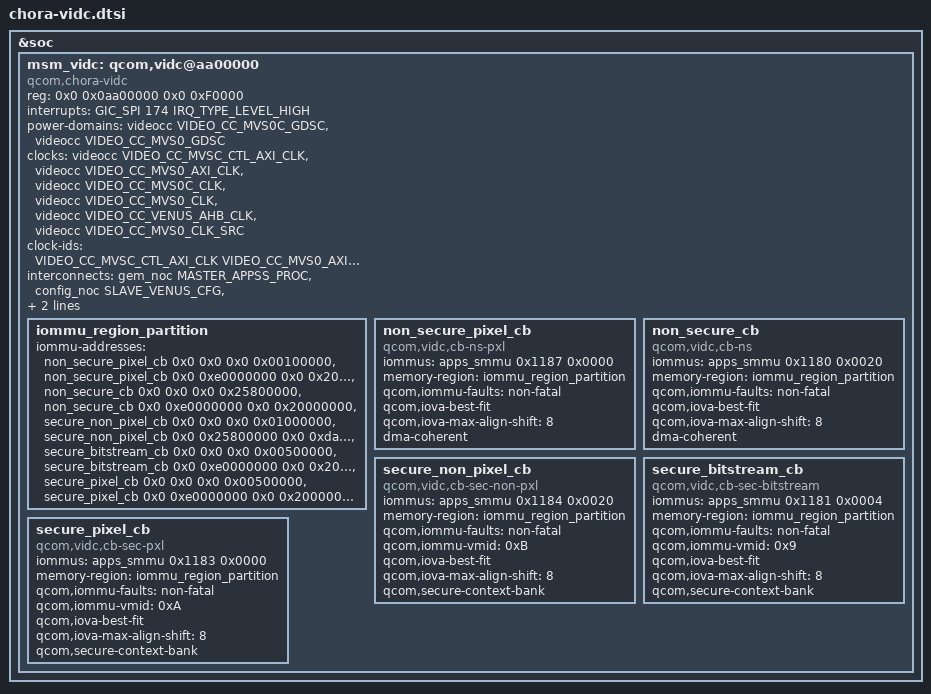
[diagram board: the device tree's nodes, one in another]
// SPDX-License-Identifier: BSD-3-Clause
/*
 * Copyright (c) Qualcomm Technologies, Inc. and/or its subsidiaries.
 */

&soc {
	msm_vidc: qcom,vidc@aa00000 {
		compatible = "qcom,chora-vidc";
		status = "okay";

		/* IOMMU Config */
		#address-cells = <2>;
		#size-cells = <2>;

		reg = <0x0 0x0aa00000 0x0  0xF0000>;
		interrupts = <GIC_SPI 174 IRQ_TYPE_LEVEL_HIGH>;

		/* Power Domains */
		power-domains = <&videocc VIDEO_CC_MVS0C_GDSC>,
				<&videocc VIDEO_CC_MVS0_GDSC>;
		power-domain-names = "iris-ctl", "vcodec";

		/* Clocks */
		clocks =
			<&videocc VIDEO_CC_MVSC_CTL_AXI_CLK>,
			<&videocc VIDEO_CC_MVS0_AXI_CLK>,
			<&videocc VIDEO_CC_MVS0C_CLK>,
			<&videocc VIDEO_CC_MVS0_CLK>,
			<&videocc VIDEO_CC_VENUS_AHB_CLK>,
			<&videocc VIDEO_CC_MVS0_CLK_SRC>;
		clock-names =
			"video_ctl_axi_clk",
			"video_mvs0_axi_clk",
			"core_clk",
			"vcodec_clk",
			"iface_clk",
			"video_cc_iris_clk_src";
		clock-ids =
			<VIDEO_CC_MVSC_CTL_AXI_CLK
			VIDEO_CC_MVS0_AXI_CLK
			VIDEO_CC_MVS0C_CLK
			VIDEO_CC_MVS0_CLK
			VIDEO_CC_VENUS_AHB_CLK
			VIDEO_CC_MVS0_CLK_SRC>;

		/* Bus Interconnects uncommenting this causing issue */
		interconnects =
			<&gem_noc MASTER_APPSS_PROC &config_noc SLAVE_VENUS_CFG>,
			<&mmss_noc MASTER_VIDEO &mc_virt SLAVE_EBI1>;
		interconnect-names =
			"venus-cnoc",
			"venus-ddr";

		memory-region = <&video_mem>;

		/* MMUs */
		iommu_region_partition: iommu_region_partition {
			/* These IOVA regions are unique per context bank */
			iommu-addresses = <&non_secure_pixel_cb 0x0 0x0 0x0 0x00100000>,
				<&non_secure_pixel_cb 0x0 0xe0000000 0x0 0x20000000>,
				<&non_secure_cb 0x0 0x0 0x0 0x25800000>,
				<&non_secure_cb 0x0 0xe0000000 0x0 0x20000000>,
				<&secure_non_pixel_cb 0x0 0x0 0x0 0x01000000>,
				<&secure_non_pixel_cb 0x0 0x25800000 0x0 0xda800000>,
				<&secure_bitstream_cb 0x0 0x0 0x0 0x00500000>,
				<&secure_bitstream_cb 0x0 0xe0000000 0x0 0x20000000>,
				<&secure_pixel_cb 0x0 0x0 0x0 0x00500000>,
				<&secure_pixel_cb 0x0 0xe0000000 0x0 0x20000000>;
		};

		non_secure_pixel_cb:non_secure_pixel_cb {
			compatible = "qcom,vidc,cb-ns-pxl";
			iommus = <&apps_smmu 0x1187 0x0000>;
			memory-region = <&iommu_region_partition>;
			qcom,iommu-faults = "non-fatal";
			qcom,iova-best-fit;
			/* log2 of desired alignment (1MB) - log2 of PAGE_SIZE; (8 = 20 - 12) */
			qcom,iova-max-align-shift = <8>;
			dma-coherent;
		};

		non_secure_cb:non_secure_cb {
			compatible = "qcom,vidc,cb-ns";
			iommus = <&apps_smmu 0x1180 0x0020>;
			memory-region = <&iommu_region_partition>;
			qcom,iommu-faults = "non-fatal";
			qcom,iova-best-fit;
			qcom,iova-max-align-shift = <8>; /* 1 MB */
			dma-coherent;
		};

		secure_non_pixel_cb:secure_non_pixel_cb {
			compatible = "qcom,vidc,cb-sec-non-pxl";
			iommus = <&apps_smmu 0x1184 0x0020>;
			memory-region = <&iommu_region_partition>;
			qcom,iommu-faults = "non-fatal";
			qcom,iommu-vmid = <0xB>; /* VMID_CP_NON_PIXEL */
			qcom,iova-best-fit;
			qcom,iova-max-align-shift = <8>; /* 1 MB */
			qcom,secure-context-bank;
		};

		secure_bitstream_cb:secure_bitstream_cb {
			compatible = "qcom,vidc,cb-sec-bitstream";
			iommus = <&apps_smmu 0x1181 0x0004>;
			memory-region = <&iommu_region_partition>;
			qcom,iommu-faults = "non-fatal";
			qcom,iommu-vmid = <0x9>; /* VMID_CP_BITSTREAM */
			qcom,iova-best-fit;
			qcom,iova-max-align-shift = <8>; /* 1 MB */
			qcom,secure-context-bank;
		};

		secure_pixel_cb:secure_pixel_cb {
			compatible = "qcom,vidc,cb-sec-pxl";
			iommus = <&apps_smmu 0x1183 0x0000>;
			memory-region = <&iommu_region_partition>;
			qcom,iommu-faults = "non-fatal";
			qcom,iommu-vmid = <0xA>; /* VMID_CP_PIXEL */
			qcom,iova-best-fit;
			qcom,iova-max-align-shift = <8>; /* 1 MB */
			qcom,secure-context-bank;
		};
	};
};
